AUTOSAR XML (schema 00052)
package /adcm/AdaptiveApplicationSwComponentTypes
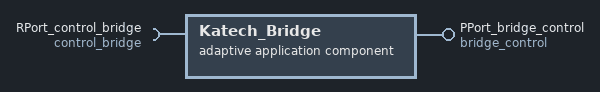
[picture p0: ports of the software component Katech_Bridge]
  adaptive application sw component type Katech_Bridge
    provide port PPort_bridge_control: provided-interface=bridge_control
    require port RPort_control_bridge: required-interface=control_bridge
package /adcm/Executables
  executable Katech_Bridge: category=APPLICATION_LEVEL, minimum-timer-granularity=1000
    root sw component prototype Katech_Bridge: application-type=Katech_Bridge
